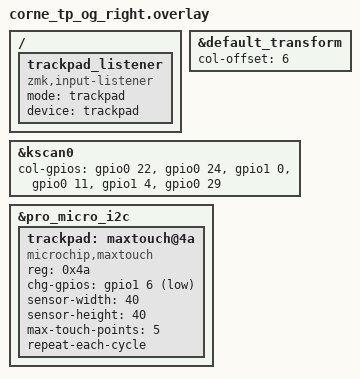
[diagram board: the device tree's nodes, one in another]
/*
 * Copyright (c) 2020 ZMK Contributors
 *
 * SPDX-License-Identifier: MIT
 */

#include "corne_tp_og.dtsi"

&default_transform {
    col-offset = <6>;
};

&kscan0 {
    col-gpios
        = <&gpio0 22 GPIO_ACTIVE_HIGH>
        , <&gpio0 24 GPIO_ACTIVE_HIGH>
        , <&gpio1 0  GPIO_ACTIVE_HIGH>
        , <&gpio0 11 GPIO_ACTIVE_HIGH>
        , <&gpio1 4  GPIO_ACTIVE_HIGH>
        , <&gpio0 29 GPIO_ACTIVE_HIGH>
        ;
};

&pro_micro_i2c {
    status = "okay";

    trackpad: maxtouch@4a {
        compatible = "microchip,maxtouch";
        reg = <0x4a>;
        status = "okay";

        chg-gpios = <&gpio1 6 (GPIO_ACTIVE_LOW | GPIO_PULL_UP)>;

        sensor-width = <40>;
        sensor-height = <40>;

        max-touch-points = <5>;
        repeat-each-cycle;
    };
};

/ {
    trackpad_listener {
        compatible = "zmk,input-listener";
        mode = "trackpad";
        device = <&trackpad>;
    };
};
